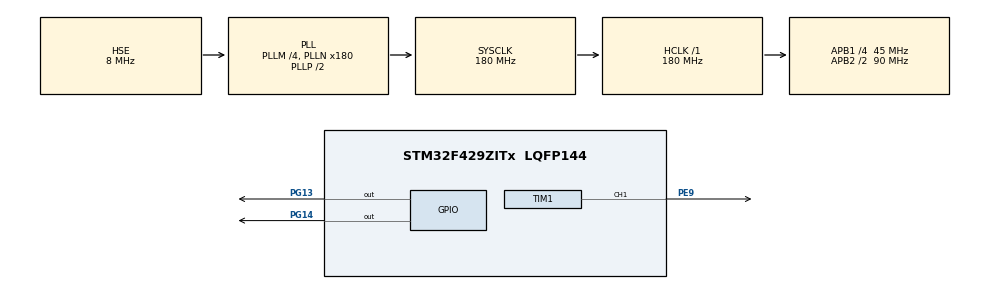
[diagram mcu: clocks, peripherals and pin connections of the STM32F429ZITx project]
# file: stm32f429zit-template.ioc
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Mcu.Family=STM32F4
Mcu.Name=STM32F429ZITx
Mcu.Package=LQFP144
NVIC.PriorityGroup=NVIC_PRIORITYGROUP_4
NVIC.TIM7_IRQn=true\:0\:0\:false\:false\:true\:true\:true\:true
PA13.Mode=Serial_Wire
PA13.Signal=SYS_JTMS-SWDIO
PA14.Mode=Serial_Wire
PA14.Signal=SYS_JTCK-SWCLK
PE9.Signal=S_TIM1_CH1
PG13.Signal=GPIO_Output
PG14.Signal=GPIO_Output
PH0/OSC_IN.Mode=HSE-External-Oscillator
PH0/OSC_IN.Signal=RCC_OSC_IN
PH1/OSC_OUT.Mode=HSE-External-Oscillator
PH1/OSC_OUT.Signal=RCC_OSC_OUT
ProjectManager.HeapSize=0x200
ProjectManager.StackSize=0x400
ProjectManager.TargetToolchain=STM32CubeIDE
RCC.48MHZClocksFreq_Value=90000000
RCC.AHBFreq_Value=180000000
RCC.APB1CLKDivider=RCC_HCLK_DIV4
RCC.APB1Freq_Value=45000000
RCC.APB1TimFreq_Value=90000000
RCC.APB2CLKDivider=RCC_HCLK_DIV2
RCC.APB2Freq_Value=90000000
RCC.APB2TimFreq_Value=180000000
RCC.CortexFreq_Value=180000000
RCC.HCLKFreq_Value=180000000
RCC.HSE_VALUE=8000000
RCC.HSI_VALUE=16000000
RCC.LSE_VALUE=32768
RCC.PLLM=4
RCC.PLLN=180
RCC.PLLSourceVirtual=RCC_PLLSOURCE_HSE
RCC.SYSCLKFreq_VALUE=180000000
RCC.SYSCLKSource=RCC_SYSCLKSOURCE_PLLCLK
RCC.VCOOutputFreq_Value=360000000
SH.S_TIM1_CH1.0=TIM1_CH1,PWM Generation1 CH1
TIM1.Channel-PWM\ Generation1\ CH1=TIM_CHANNEL_1
TIM1.CounterMode=TIM_COUNTERMODE_CENTERALIGNED1
TIM7.Period=10000-1
TIM7.Prescaler=8000-1
VP_TIM7_VS_ClockSourceINT.Mode=Enable_Timer
board=custom

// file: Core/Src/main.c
/* USER CODE BEGIN Header */
/**
  ******************************************************************************
  * @file           : main.c
  * @brief          : Main program body
  ******************************************************************************
  * @attention
  *
  * Copyright (c) 2024 STMicroelectronics.
  * All rights reserved.
  *
  * This software is licensed under terms that can be found in the LICENSE file
  * in the root directory of this software component.
  * If no LICENSE file comes with this software, it is provided AS-IS.
  *
  ******************************************************************************
  */
/* USER CODE END Header */
#include "main.h"

TIM_HandleTypeDef htim1;
TIM_HandleTypeDef htim7;

void SystemClock_Config(void);
static void MX_GPIO_Init(void);
static void MX_TIM7_Init(void);
static void MX_TIM1_Init(void);

int main(void)
{

  /* MCU Configuration--------------------------------------------------------*/

  /* Reset of all peripherals, Initializes the Flash interface and the Systick. */
  HAL_Init();

  /* Configure the system clock */
  SystemClock_Config();

  /* Initialize all configured peripherals */
  MX_GPIO_Init();
  MX_TIM7_Init();
  MX_TIM1_Init();
  /* USER CODE BEGIN 2 */
  HAL_TIM_Base_Start_IT(&htim7);

  TIM1->ARR = SystemCoreClock / 10000;
  TIM1->CCR1 = (uint16_t)(0.25f * (float)TIM1->ARR);
  HAL_TIM_PWM_Start(&htim1, TIM_CHANNEL_1);
  /* USER CODE END 2 */

  /* Infinite loop */
  while (1)
  {

  }
}

void SystemClock_Config(void)
{
  RCC_OscInitTypeDef RCC_OscInitStruct = {0};
  RCC_ClkInitTypeDef RCC_ClkInitStruct = {0};

  /** Configure the main internal regulator output voltage
  */
  __HAL_RCC_PWR_CLK_ENABLE();
  __HAL_PWR_VOLTAGESCALING_CONFIG(PWR_REGULATOR_VOLTAGE_SCALE1);

  /** Initializes the RCC Oscillators according to the specified parameters
  * in the RCC_OscInitTypeDef structure.
  */
  RCC_OscInitStruct.OscillatorType = RCC_OSCILLATORTYPE_HSE;
  RCC_OscInitStruct.HSEState = RCC_HSE_ON;
  RCC_OscInitStruct.PLL.PLLState = RCC_PLL_ON;
  RCC_OscInitStruct.PLL.PLLSource = RCC_PLLSOURCE_HSE;
  RCC_OscInitStruct.PLL.PLLM = 4;
  RCC_OscInitStruct.PLL.PLLN = 180;
  RCC_OscInitStruct.PLL.PLLP = RCC_PLLP_DIV2;
  RCC_OscInitStruct.PLL.PLLQ = 4;
  if (HAL_RCC_OscConfig(&RCC_OscInitStruct) != HAL_OK)
  {
    Error_Handler();
  }

  /** Activate the Over-Drive mode
  */
  if (HAL_PWREx_EnableOverDrive() != HAL_OK)
  {
    Error_Handler();
  }

  /** Initializes the CPU, AHB and APB buses clocks
  */
  RCC_ClkInitStruct.ClockType = RCC_CLOCKTYPE_HCLK|RCC_CLOCKTYPE_SYSCLK
                              |RCC_CLOCKTYPE_PCLK1|RCC_CLOCKTYPE_PCLK2;
  RCC_ClkInitStruct.SYSCLKSource = RCC_SYSCLKSOURCE_PLLCLK;
  RCC_ClkInitStruct.AHBCLKDivider = RCC_SYSCLK_DIV1;
  RCC_ClkInitStruct.APB1CLKDivider = RCC_HCLK_DIV4;
  RCC_ClkInitStruct.APB2CLKDivider = RCC_HCLK_DIV2;

  if (HAL_RCC_ClockConfig(&RCC_ClkInitStruct, FLASH_LATENCY_5) != HAL_OK)
  {
    Error_Handler();
  }
}

static void MX_TIM1_Init(void)
{

  TIM_MasterConfigTypeDef sMasterConfig = {0};
  TIM_OC_InitTypeDef sConfigOC = {0};
  TIM_BreakDeadTimeConfigTypeDef sBreakDeadTimeConfig = {0};

  htim1.Instance = TIM1;
  htim1.Init.Prescaler = 0;
  htim1.Init.CounterMode = TIM_COUNTERMODE_CENTERALIGNED1;
  htim1.Init.Period = 65535;
  htim1.Init.ClockDivision = TIM_CLOCKDIVISION_DIV1;
  htim1.Init.RepetitionCounter = 0;
  htim1.Init.AutoReloadPreload = TIM_AUTORELOAD_PRELOAD_DISABLE;
  if (HAL_TIM_PWM_Init(&htim1) != HAL_OK)
  {
    Error_Handler();
  }
  sMasterConfig.MasterOutputTrigger = TIM_TRGO_RESET;
  sMasterConfig.MasterSlaveMode = TIM_MASTERSLAVEMODE_DISABLE;
  if (HAL_TIMEx_MasterConfigSynchronization(&htim1, &sMasterConfig) != HAL_OK)
  {
    Error_Handler();
  }
  sConfigOC.OCMode = TIM_OCMODE_PWM1;
  sConfigOC.Pulse = 0;
  sConfigOC.OCPolarity = TIM_OCPOLARITY_HIGH;
  sConfigOC.OCNPolarity = TIM_OCNPOLARITY_HIGH;
  sConfigOC.OCFastMode = TIM_OCFAST_DISABLE;
  sConfigOC.OCIdleState = TIM_OCIDLESTATE_RESET;
  sConfigOC.OCNIdleState = TIM_OCNIDLESTATE_RESET;
  if (HAL_TIM_PWM_ConfigChannel(&htim1, &sConfigOC, TIM_CHANNEL_1) != HAL_OK)
  {
    Error_Handler();
  }
  sBreakDeadTimeConfig.OffStateRunMode = TIM_OSSR_DISABLE;
  sBreakDeadTimeConfig.OffStateIDLEMode = TIM_OSSI_DISABLE;
  sBreakDeadTimeConfig.LockLevel = TIM_LOCKLEVEL_OFF;
  sBreakDeadTimeConfig.DeadTime = 0;
  sBreakDeadTimeConfig.BreakState = TIM_BREAK_DISABLE;
  sBreakDeadTimeConfig.BreakPolarity = TIM_BREAKPOLARITY_HIGH;
  sBreakDeadTimeConfig.AutomaticOutput = TIM_AUTOMATICOUTPUT_DISABLE;
  if (HAL_TIMEx_ConfigBreakDeadTime(&htim1, &sBreakDeadTimeConfig) != HAL_OK)
  {
    Error_Handler();
  }
  HAL_TIM_MspPostInit(&htim1);

}

static void MX_TIM7_Init(void)
{

  TIM_MasterConfigTypeDef sMasterConfig = {0};

  htim7.Instance = TIM7;
  htim7.Init.Prescaler = 8000-1;
  htim7.Init.CounterMode = TIM_COUNTERMODE_UP;
  htim7.Init.Period = 10000-1;
  htim7.Init.AutoReloadPreload = TIM_AUTORELOAD_PRELOAD_DISABLE;
  if (HAL_TIM_Base_Init(&htim7) != HAL_OK)
  {
    Error_Handler();
  }
  sMasterConfig.MasterOutputTrigger = TIM_TRGO_RESET;
  sMasterConfig.MasterSlaveMode = TIM_MASTERSLAVEMODE_DISABLE;
  if (HAL_TIMEx_MasterConfigSynchronization(&htim7, &sMasterConfig) != HAL_OK)
  {
    Error_Handler();
  }

}

static void MX_GPIO_Init(void)
{
  GPIO_InitTypeDef GPIO_InitStruct = {0};

  /* GPIO Ports Clock Enable */
  __HAL_RCC_GPIOH_CLK_ENABLE();
  __HAL_RCC_GPIOE_CLK_ENABLE();
  __HAL_RCC_GPIOA_CLK_ENABLE();
  __HAL_RCC_GPIOG_CLK_ENABLE();

  /*Configure GPIO pin Output Level */
  HAL_GPIO_WritePin(GPIOG, GPIO_PIN_13|GPIO_PIN_14, GPIO_PIN_RESET);

  /*Configure GPIO pins : PG13 PG14 */
  GPIO_InitStruct.Pin = GPIO_PIN_13|GPIO_PIN_14;
  GPIO_InitStruct.Mode = GPIO_MODE_OUTPUT_PP;
  GPIO_InitStruct.Pull = GPIO_NOPULL;
  GPIO_InitStruct.Speed = GPIO_SPEED_FREQ_LOW;
  HAL_GPIO_Init(GPIOG, &GPIO_InitStruct);

}

/* USER CODE BEGIN 4 */
void HAL_TIM_PeriodElapsedCallback(TIM_HandleTypeDef *htim)
{
  // Этот обратный вызов автоматически вызывается HAL при возникновении события UEV
  // Передача управления HAL, который обрабатывает IRQ
  if (htim == &htim7) {
    HAL_GPIO_TogglePin(GPIOG, GPIO_PIN_13);
  }
}
/* USER CODE END 4 */

void Error_Handler(void)
{
  __disable_irq();
  while (1)
  {
  }
}
